# R7FA6M2AF register map
Vendor: Renesas; Series: RA6; File version: 1.2
CPU: CM4 r0p1, little endian, MPU, FPU, VTOR, 4 interrupt priority bits
Registers are 8-bit, read-write, reset 0x0 unless marked. A register's access mark holds for its fields unless they carry their own. Offsets are from the block's base; [hi:lo] are bit positions; {n}, {i} and the like mark numbered series.

## MSTP — Module Stop Control B,C,D
Base 0x40047000
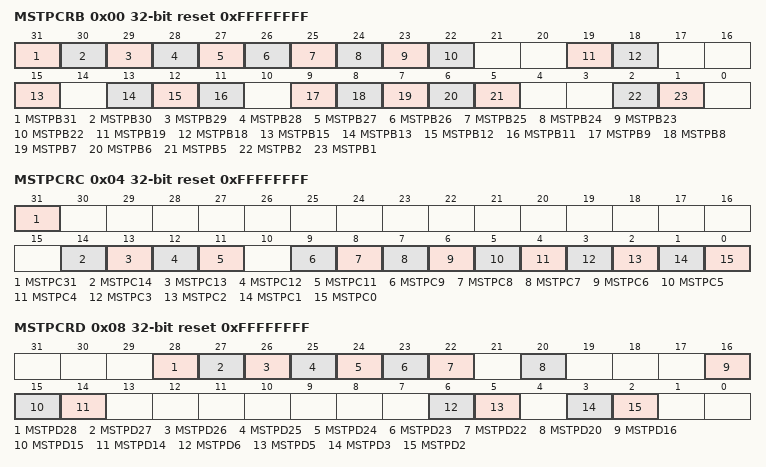
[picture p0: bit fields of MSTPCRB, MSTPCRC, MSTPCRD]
0x00 MSTPCRB 32-bit reset 0xFFFFFFFF — Module Stop Control Register B
  [31] MSTPB31 — Serial Communication Interface 0 Module Stop
  [30] MSTPB30 — Serial Communication Interface 1 Module Stop
  [29] MSTPB29 — Serial Communication Interface 2 Module Stop
  [28] MSTPB28 — Serial Communication Interface 3 Module Stop
  [27] MSTPB27 — Serial Communication Interface 4 Module Stop
  [26] MSTPB26 — Serial Communication Interface 5 Module Stop
  [25] MSTPB25 — Serial Communication Interface 6 Module Stop
  [24] MSTPB24 — Serial Communication Interface 7 Module Stop
  [23] MSTPB23 — Serial Communication Interface 8 Module Stop
  [22] MSTPB22 — Serial Communication Interface 9 Module Stop
  [19] MSTPB19 — Serial Peripheral Interface 0 Module Stop
  [18] MSTPB18 — Serial Peripheral Interface Module Stop
  [15] MSTPB15 — ETHERC0 and EDMAC0 Module Stop
  [13] MSTPB13 — EPTPC and PTPEDMAC Module Stop
  [12] MSTPB12 — Universal Serial Bus 2.0 HS Interface Module Stop
  [11] MSTPB11 — Universal Serial Bus 2.0 FS Interface Module Stop
  [9] MSTPB9 — I2C Bus Interface 0 Module Stop
  [8] MSTPB8 — I2C Bus Interface 1 Module Stop
  [7] MSTPB7 — I2C Bus Interface 2 Module Stop
  [6] MSTPB6 — Queued Serial Peripheral Interface Module Stop
  [5] MSTPB5 — IrDA Module Stop
  [2] MSTPB2 — RCAN0 Module Stop
  [1] MSTPB1 — RCAN1 Module Stop
0x04 MSTPCRC 32-bit reset 0xFFFFFFFF — Module Stop Control Register C
  [31] MSTPC31 — TSIP Module Stop
  [14] MSTPC14 — Event Link Controller Module Stop
  [13] MSTPC13 — Data Operation Circuit Module Stop
  [12] MSTPC12 — Synchronous Digital Hierarchy/ Multi Media Card 0 Module Stop
  [11] MSTPC11 — Synchronous Digital Hierarchy/ Multi Media Card 1 Module Stop
  [9] MSTPC9 — Sampling Rate Converter Module Stop
  [8] MSTPC8 — Synchronous Serial Interface 0 Module Stop
  [7] MSTPC7 — Synchronous Serial Interface 1 Module Stop
  [6] MSTPC6 — 2DG engine Module Stop
  [5] MSTPC5 — JPEG codec engine Module Stop
  [4] MSTPC4 — Grafic LCD Controler Module Stop
  [3] MSTPC3 — Capacitive Touch Sensing Unit Module Stop
  [2] MSTPC2 — Parallel Data Capture Module Stop
  [1] MSTPC1 — CRC Calculator Module Stop
  [0] MSTPC0 — CAC Module Stop
0x08 MSTPCRD 32-bit reset 0xFFFFFFFF — Module Stop Control Register D
  [28] MSTPD28 — Comparator,OC0 Module Stop
  [27] MSTPD27 — Comparator,OC1 Module Stop
  [26] MSTPD26 — Comparator,OC2 Module Stop
  [25] MSTPD25 — Comparator,OC3 Module Stop
  [24] MSTPD24 — Comparator,OC4 Module Stop
  [23] MSTPD23 — Comparator,OC5 Module Stop
  [22] MSTPD22 — Temperature Sensor Module Stop
  [20] MSTPD20 — D/A Converter 0 Module Stop
  [16] MSTPD16 — 12-bit A/D Converter 0 Module Stop
  [15] MSTPD15 — 12-bit A/D Converter 1 Module Stop
  [14] MSTPD14 — PGI Module Stop
  [6] MSTPD6 — GPT ch13-ch8 Module Stop
  [5] MSTPD5 — GPT ch7-ch0 Module Stop
  [3] MSTPD3 — AGT0 Module StopNote: AGT0 is in the module stop state when the count source is either of PCLKB, PCLKB/2 or PCLKB/8. In case the count source is sub,clock or LOCO, this bit should be set to 1 except when accessing the registers of AGT0.
  [2] MSTPD2 — AGT1 Module StopNote: AGT1 is in the module stop state when the count source is either of PCLKB, PCLKB/2 or PCLKB/8. In case the count source is sub,clock or LOCO, this bit should be set to 1 except when accessing the registers of AGT1.

## SRCRAM — Sampling Rate Converter RAM
Base 0x40048000
{0x0+4i} SRCFCTR[{i}] (i=0..5551) 32-bit (reset mask 0xFFC00000) — Filter Coefficient Table [{i}]
  [21:0] SRCFCOE — Stores a filter coefficient value.

## SRC — Sampling Rate Converter
Base 0x4004DFF0
0x00 SRCID 32-bit wo — Input Data Register
  [31:0] SRCID — SRCID is a 32-bit writ,only register that is used to input the data before sampling rate conversion. All the bits are read as 0.
0x04 SRCOD 32-bit ro — Output Data Register
  [31:0] SRCOD — SRCOD is a 32-bit read,only register used to output the data after sampling rate conversion. The data in the 16-stage output data FIFO is read through SRCOD. When the number of data in the output data FIFO is zero after the start of conversion, the value previously read is read again.
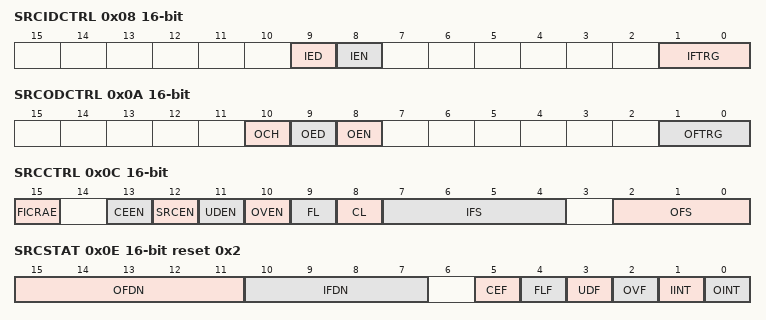
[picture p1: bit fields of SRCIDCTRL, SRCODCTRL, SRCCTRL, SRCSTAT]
0x08 SRCIDCTRL 16-bit — Input Data Control Register
  [9] IED — Input Data Endian
  [8] IEN — Input FIFO Empty Interrupt Enable
  [1:0] IFTRG — Input FIFO Data Triggering Number
0x0A SRCODCTRL 16-bit — Output Data Control Register
  [10] OCH — Output Data Channel Exchange
  [9] OED — Output Data Endian
  [8] OEN — Output Data FIFO Full Interrupt Enable
  [1:0] OFTRG — Output FIFO Data Trigger Number
0x0C SRCCTRL 16-bit — Control Register
  [15] FICRAE — Filter Coefficient Table Access Enable
  [13] CEEN — Conversion End Interrupt Enable
  [12] SRCEN — Module Enable
  [11] UDEN — Output Data FIFO Underflow Interrupt Enable
  [10] OVEN — Output Data FIFO Overwrite Interrupt Enable
  [9] FL wo — Internal Work Memory Flush
  [8] CL wo — Internal Work Memory Clear
  [7:4] IFS — Input Sampling Rate
  [2:0] OFS — Output Sampling Rate
0x0E SRCSTAT 16-bit reset 0x2 — Status Register
  [15:11] OFDN ro — Output FIFO Data Count
  [10:7] IFDN ro — Input FIFO Data Count
  [5] CEF write-0-clears read-modifies — Conversion End Flag
  [4] FLF ro — Flush Processing Status Flag
  [3] UDF write-0-clears read-modifies — Output FIFO Underflow Interrupt Request Flag
  [2] OVF write-0-clears read-modifies — Output Data FIFO Overwrite Interrupt Request Flag
  [1] IINT write-0-clears read-modifies — Input Data FIFO Empty Interrupt Request Flag
  [0] OINT write-0-clears read-modifies — Output Data FIFO Full Interrupt Request Flag
